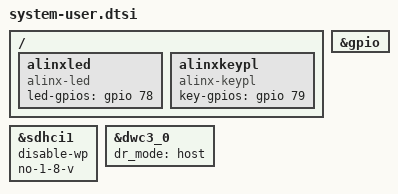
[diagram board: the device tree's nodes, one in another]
#include <dt-bindings/gpio/gpio.h>
#include <dt-bindings/pinctrl/pinctrl-zynqmp.h>

/include/ "system-conf.dtsi"
/ {
	alinxled {  
		compatible = "alinx-led";  
		led-gpios = <&gpio 78 GPIO_ACTIVE_HIGH>;
	};

	alinxkeypl {
		compatible = "alinx-keypl"; 
		key-gpios = <&gpio 79 GPIO_PULL_UP>;
	};
};

/* SD */
&sdhci1 {
	disable-wp;
	no-1-8-v;
};

/* USB  */
&dwc3_0 {
	status = "okay";
	dr_mode = "host";
};

&gpio {
	status = "okay";
};


